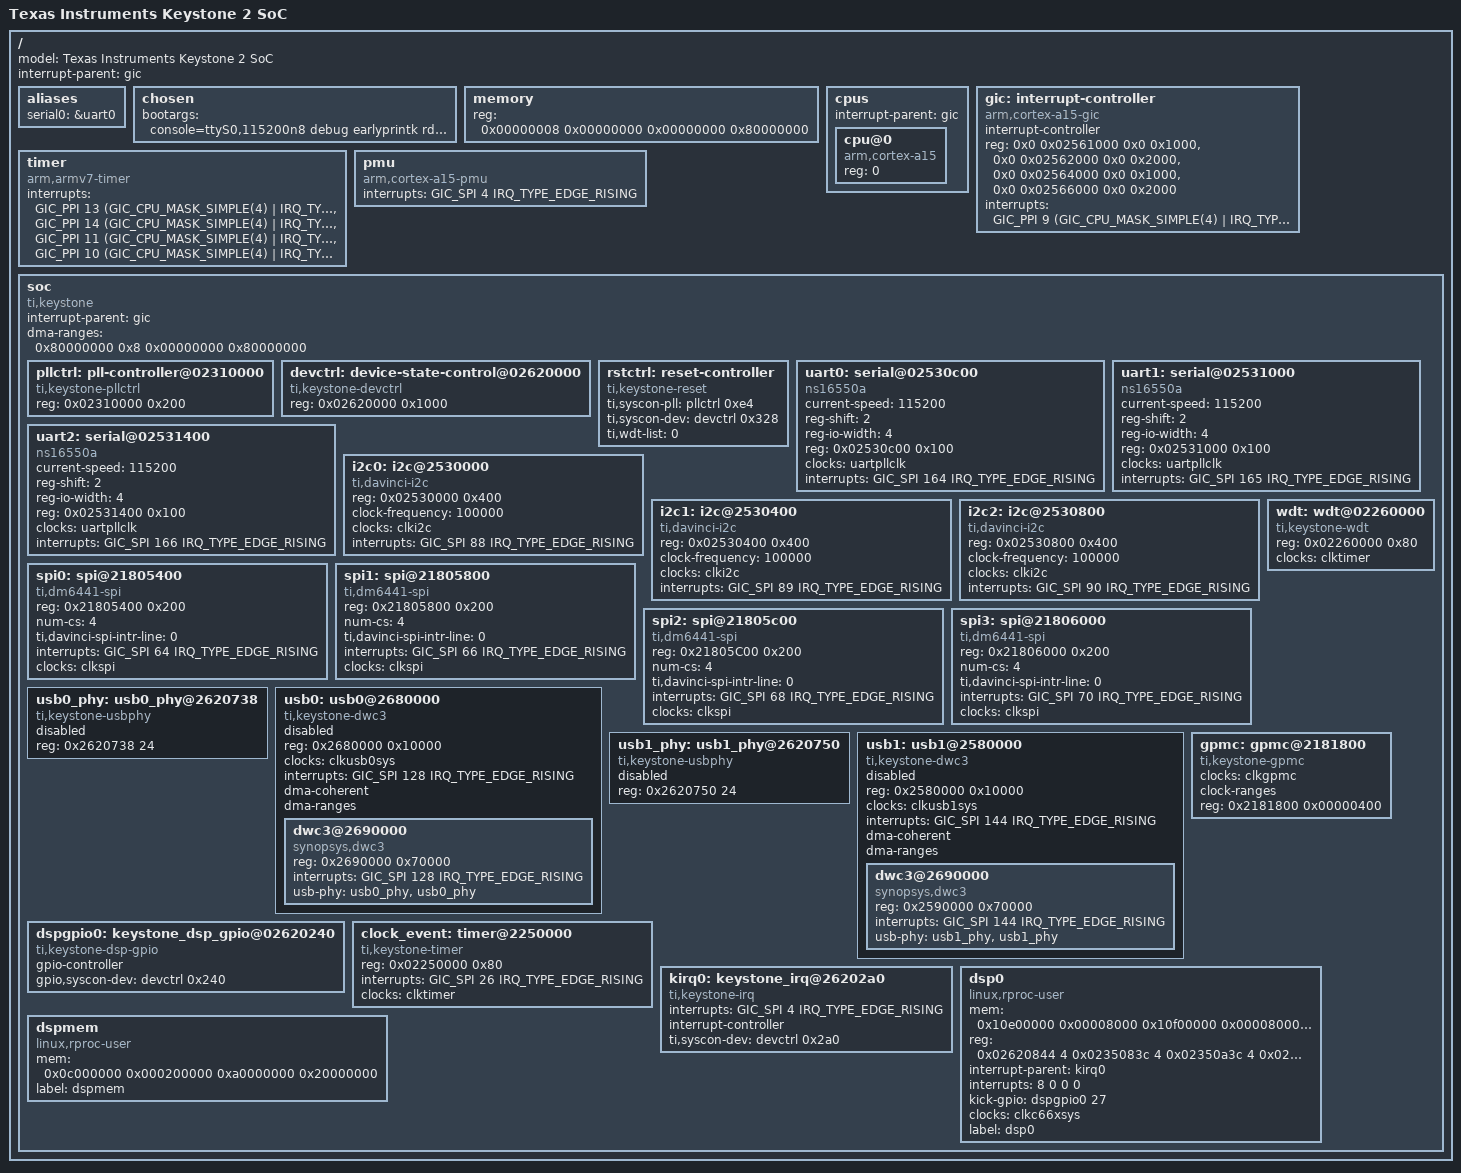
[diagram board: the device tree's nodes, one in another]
/*
 * Copyright 2014 Texas Instruments, Inc.
 *
 * Keystone 2 Galileo soc device tree
 *
 * This program is free software; you can redistribute it and/or modify
 * it under the terms of the GNU General Public License version 2 as
 * published by the Free Software Foundation.
 */

#include <dt-bindings/interrupt-controller/arm-gic.h>
#include <dt-bindings/gpio/gpio.h>
#include "skeleton.dtsi"

/ {
	model = "Texas Instruments Keystone 2 SoC";
	#address-cells = <2>;
	#size-cells = <2>;
	interrupt-parent = <&gic>;

	aliases {
		serial0	= &uart0;
	};

	chosen {
		bootargs = "console=ttyS0,115200n8 debug earlyprintk rdinit=/sbin/init rw root=/dev/ram0 nosmp initrd=0x802000000,9M";
	};

	memory {
		device_type = "memory";
		reg = <0x00000008 0x00000000 0x00000000 0x80000000>;
	};

	cpus {
		#address-cells = <1>;
		#size-cells = <0>;

		interrupt-parent = <&gic>;

		cpu@0 {
			compatible = "arm,cortex-a15";
			device_type = "cpu";
			reg = <0>;
		};
	};

	gic: interrupt-controller {
		compatible = "arm,cortex-a15-gic";
		#interrupt-cells = <3>;
		interrupt-controller;
		reg = <0x0 0x02561000 0x0 0x1000>,
		      <0x0 0x02562000 0x0 0x2000>,
		      <0x0 0x02564000 0x0 0x1000>,
		      <0x0 0x02566000 0x0 0x2000>;
		interrupts = <GIC_PPI 9 (GIC_CPU_MASK_SIMPLE(4) |
				IRQ_TYPE_LEVEL_HIGH)>;
	};

	timer {
		compatible = "arm,armv7-timer";
		interrupts =
			<GIC_PPI 13
				(GIC_CPU_MASK_SIMPLE(4) | IRQ_TYPE_LEVEL_LOW)>,
			<GIC_PPI 14
				(GIC_CPU_MASK_SIMPLE(4) | IRQ_TYPE_LEVEL_LOW)>,
			<GIC_PPI 11
				(GIC_CPU_MASK_SIMPLE(4) | IRQ_TYPE_LEVEL_LOW)>,
			<GIC_PPI 10
				(GIC_CPU_MASK_SIMPLE(4) | IRQ_TYPE_LEVEL_LOW)>;
	};

	pmu {
		compatible = "arm,cortex-a15-pmu";
		interrupts = <GIC_SPI 4 IRQ_TYPE_EDGE_RISING>;
	};

	soc {
		#address-cells = <1>;
		#size-cells = <1>;
		compatible = "ti,keystone","simple-bus";
		interrupt-parent = <&gic>;
		ranges = <0x0 0x0 0x0 0xc0000000>;
		dma-ranges = <0x80000000 0x8 0x00000000 0x80000000>;

		pllctrl: pll-controller@02310000 {
			compatible = "ti,keystone-pllctrl", "syscon";
			reg = <0x02310000 0x200>;
		};

		devctrl: device-state-control@02620000 {
			compatible = "ti,keystone-devctrl", "syscon";
			reg = <0x02620000 0x1000>;
		};

		rstctrl: reset-controller {
			compatible = "ti,keystone-reset";
			ti,syscon-pll = <&pllctrl 0xe4>;
			ti,syscon-dev = <&devctrl 0x328>;
			ti,wdt-list = <0>;
		};

		/include/ "k2g-clocks.dtsi"

		uart0: serial@02530c00 {
			compatible = "ns16550a";
			current-speed = <115200>;
			reg-shift = <2>;
			reg-io-width = <4>;
			reg = <0x02530c00 0x100>;
			clocks	= <&uartpllclk>;
			interrupts = <GIC_SPI 164 IRQ_TYPE_EDGE_RISING>;
		};

		uart1:	serial@02531000 {
			compatible = "ns16550a";
			current-speed = <115200>;
			reg-shift = <2>;
			reg-io-width = <4>;
			reg = <0x02531000 0x100>;
			clocks	= <&uartpllclk>;
			interrupts = <GIC_SPI 165 IRQ_TYPE_EDGE_RISING>;
		};

		uart2:	serial@02531400 {
			compatible = "ns16550a";
			current-speed = <115200>;
			reg-shift = <2>;
			reg-io-width = <4>;
			reg = <0x02531400 0x100>;
			clocks	= <&uartpllclk>;
			interrupts = <GIC_SPI 166 IRQ_TYPE_EDGE_RISING>;
		};

		i2c0: i2c@2530000 {
			compatible = "ti,davinci-i2c";
			reg = <0x02530000 0x400>;
			clock-frequency = <100000>;
			clocks = <&clki2c>;
			interrupts = <GIC_SPI 88 IRQ_TYPE_EDGE_RISING>;
			#address-cells = <1>;
			#size-cells = <0>;
		};

		i2c1: i2c@2530400 {
			compatible = "ti,davinci-i2c";
			reg = <0x02530400 0x400>;
			clock-frequency = <100000>;
			clocks = <&clki2c>;
			interrupts = <GIC_SPI 89 IRQ_TYPE_EDGE_RISING>;
			#address-cells = <1>;
			#size-cells = <0>;
		};

		i2c2: i2c@2530800 {
			compatible = "ti,davinci-i2c";
			reg = <0x02530800 0x400>;
			clock-frequency = <100000>;
			clocks = <&clki2c>;
			interrupts = <GIC_SPI 90 IRQ_TYPE_EDGE_RISING>;
			#address-cells = <1>;
			#size-cells = <0>;
		};

		spi0: spi@21805400 {
			compatible = "ti,dm6441-spi";
			reg = <0x21805400 0x200>;
			num-cs = <4>;
			ti,davinci-spi-intr-line = <0>;
			interrupts = <GIC_SPI 64 IRQ_TYPE_EDGE_RISING>;
			clocks = <&clkspi>;
			#address-cells = <1>;
			#size-cells = <0>;
		};

		spi1: spi@21805800 {
			compatible = "ti,dm6441-spi";
			reg = <0x21805800 0x200>;
			num-cs = <4>;
			ti,davinci-spi-intr-line = <0>;
			interrupts = <GIC_SPI 66 IRQ_TYPE_EDGE_RISING>;
			clocks = <&clkspi>;
			#address-cells = <1>;
			#size-cells = <0>;
		};

		spi2: spi@21805c00 {
			compatible = "ti,dm6441-spi";
			reg = <0x21805C00 0x200>;
			num-cs = <4>;
			ti,davinci-spi-intr-line = <0>;
			interrupts = <GIC_SPI 68 IRQ_TYPE_EDGE_RISING>;
			clocks = <&clkspi>;
			#address-cells = <1>;
			#size-cells = <0>;
		};

		spi3: spi@21806000 {
			compatible = "ti,dm6441-spi";
			reg = <0x21806000 0x200>;
			num-cs = <4>;
			ti,davinci-spi-intr-line = <0>;
			interrupts = <GIC_SPI 70 IRQ_TYPE_EDGE_RISING>;
			clocks = <&clkspi>;
			#address-cells = <1>;
			#size-cells = <0>;
		};

		usb0_phy: usb0_phy@2620738 {
			compatible = "ti,keystone-usbphy";
			#address-cells = <1>;
			#size-cells = <1>;
			reg = <0x2620738 24>;
			status = "disabled";
		};

/* TODO: check USB0 interrupt number */
		usb0: usb0@2680000 {
			compatible = "ti,keystone-dwc3";
			#address-cells = <1>;
			#size-cells = <1>;
			reg = <0x2680000 0x10000>;
			clocks = <&clkusb0sys>;
			clock-names = "usb0";
			interrupts = <GIC_SPI 128 IRQ_TYPE_EDGE_RISING>;
			ranges;
			dma-coherent;
			dma-ranges;
			status = "disabled";

			dwc3@2690000 {
				compatible = "synopsys,dwc3";
				reg = <0x2690000 0x70000>;
				interrupts = <GIC_SPI 128 IRQ_TYPE_EDGE_RISING>;
				usb-phy = <&usb0_phy>, <&usb0_phy>;
			};
		};

		usb1_phy: usb1_phy@2620750 {
			compatible = "ti,keystone-usbphy";
			#address-cells = <1>;
			#size-cells = <1>;
			reg = <0x2620750 24>;
			status = "disabled";
		};

/* TODO: check USB1 interrupt number */
		usb1: usb1@2580000 {
			compatible = "ti,keystone-dwc3";
			#address-cells = <1>;
			#size-cells = <1>;
			reg = <0x2580000 0x10000>;
			clocks = <&clkusb1sys>;
			clock-names = "usb1";
			interrupts = <GIC_SPI 144 IRQ_TYPE_EDGE_RISING>;
			ranges;
			dma-coherent;
			dma-ranges;
			status = "disabled";

			dwc3@2690000 {
				compatible = "synopsys,dwc3";
				reg = <0x2590000 0x70000>;
				interrupts = <GIC_SPI 144 IRQ_TYPE_EDGE_RISING>;
				usb-phy = <&usb1_phy>, <&usb1_phy>;
			};
		};

		dspgpio0: keystone_dsp_gpio@02620240 {
			compatible = "ti,keystone-dsp-gpio";
			gpio-controller;
			#gpio-cells = <2>;
			gpio,syscon-dev = <&devctrl 0x240>;
		};

		wdt: wdt@02260000 {
			compatible = "ti,keystone-wdt","ti,davinci-wdt";
			reg = <0x02260000 0x80>;
			clocks = <&clktimer>;
		};

		clock_event: timer@2250000 {
			compatible = "ti,keystone-timer";
			reg = <0x02250000 0x80>;
			interrupts = <GIC_SPI 26 IRQ_TYPE_EDGE_RISING>;
			clocks = <&clktimer>;
		};

		gpmc: gpmc@2181800 {
			compatible = "ti,keystone-gpmc";
			#address-cells = <2>;
			#size-cells = <1>;
			clocks = <&clkgpmc>;
			clock-names = "gpmc";
			clock-ranges;

			reg = <0x2181800 0x00000400>;
			ranges = <0 0 0x30000000 0x10000000
				  1 0 0x21818000 0x00000400>;
		};

		kirq0: keystone_irq@26202a0 {
			compatible = "ti,keystone-irq";
			interrupts = <GIC_SPI 4 IRQ_TYPE_EDGE_RISING>;
			interrupt-controller;
			#interrupt-cells = <1>;
			ti,syscon-dev = <&devctrl 0x2a0>;
		};

		dsp0: dsp0 {
			compatible = "linux,rproc-user";
			mem = <0x10e00000 0x00008000
			       0x10f00000 0x00008000
			       0x10800000 0x00100000>;
			reg = <0x02620844 4
			       0x0235083c 4
			       0x02350a3c 4
			       0x02620240 4>;
			reg-names = "boot-address", "psc-mdstat", "psc-mdctl",
				"ipcgr";
			interrupt-parent = <&kirq0>;
			interrupts = <8 0 0 0>;
			kick-gpio = <&dspgpio0 27 0>;
			clocks = <&clkc66xsys>;
			label = "dsp0";
		};

		dspmem: dspmem {
			compatible = "linux,rproc-user";
			mem  = <0x0c000000 0x000200000
					0xa0000000 0x20000000>;
			label = "dspmem";
		};

		/include/ "k2g-netcp.dtsi"

		/* kirq0: keystone_irq@26202a0 */

	}; /* soc */
};

